# STM32WB30CEU6A register map
File version: 1.0
Registers are 32-bit, access not given, reset 0x0 unless marked. A register's access mark holds for its fields unless they carry their own. Offsets are from the block's base; [hi:lo] are bit positions; {n}, {i} and the like mark numbered series; 'fields as' and 'values as' point back to an identical list.

## TIM16
Base 0x40014400
Same registers: TIM17 0x40014800
0x00 CR1
  [11] UIFREMA, [9:8] CKD, [7] ARPE, [31:4] s, [3] OPM, [2] URS, [1] UDIS, [0] CEN
0x04 CR2
  [9] OIS1N, [8] OIS1, [3] CCDS, [2] CCUS, [31:1] s, [0] CCPC
0x0C DIER
  [9] CC1DE, [8] UDE, [7] BIE, [5] COMIE, [31:2] s, [1] CC1IE, [0] UIE
0x10 SR
  [9] CC1OF, [7] BIF, [5] COMIF, [31:2] s, [1] CC1IF, [0] UIF
0x14 EGR
  [7] BG, [5] COMG, [31:2] s, [1] CC1G, [0] UG
0x18 CCMR1_OUT
  [31:8] s, [16:4] OC1M, [3] OC1PE, [2] OC1FE, [1:0] CC1S
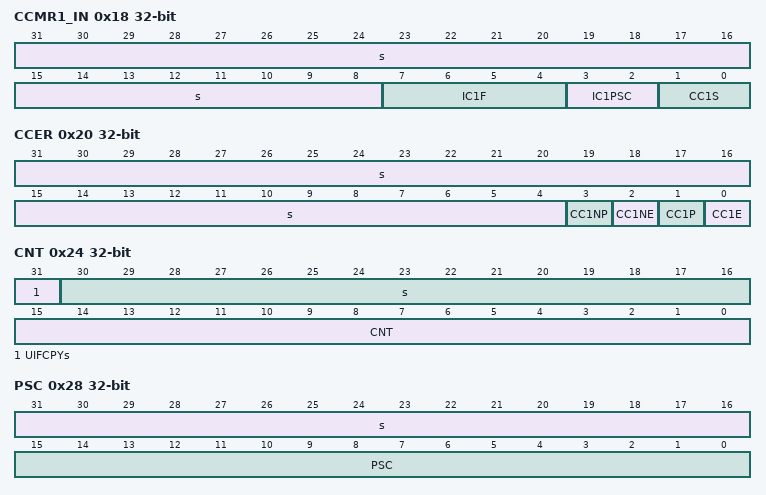
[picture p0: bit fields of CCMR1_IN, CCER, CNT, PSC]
0x18 CCMR1_IN
  [31:8] s, [7:4] IC1F, [3:2] IC1PSC, [1:0] CC1S
0x20 CCER
  [31:4] s, [3] CC1NP, [2] CC1NE, [1] CC1P, [0] CC1E
0x24 CNT
  [31] UIFCPYs, [30:16] s, [15:0] CNT
0x28 PSC
  [31:16] s, [15:0] PSC
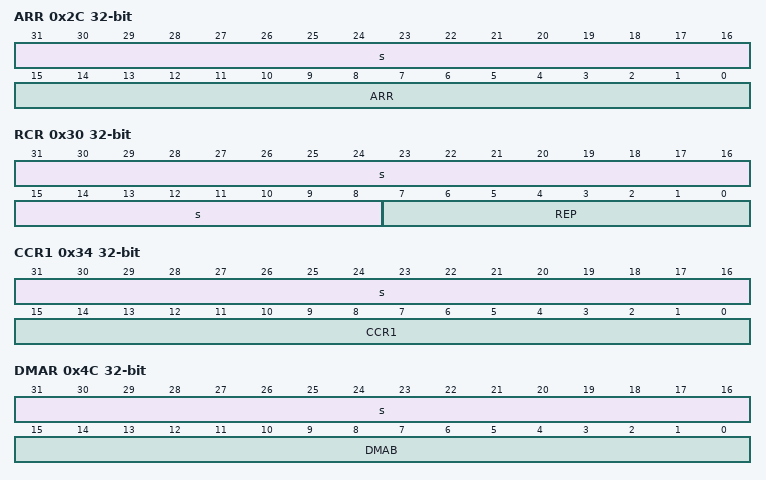
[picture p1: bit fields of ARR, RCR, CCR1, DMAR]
0x2C ARR
  [31:16] s, [15:0] ARR
0x30 RCR
  [31:8] s, [7:0] REP
0x34 CCR1
  [31:16] s, [15:0] CCR1
0x44 BDTR
  [28] BKBID, [26] BKDSRM, [31:16] s, [15] MOE, [14] AOE, [13] BKP, [12] BKE, [11] OSSR, [10] OSSI, [9:8] LOCK, [7:0] DTG
0x48 DCR
  [12:8] DBL, [31:5] s, [4:0] DBA
0x4C DMAR
  [31:16] s, [15:0] DMAB
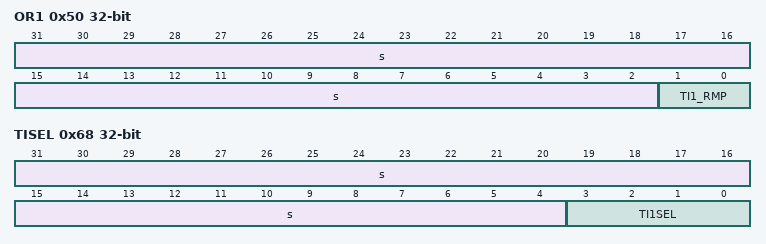
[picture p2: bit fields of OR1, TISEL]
0x50 OR1
  [31:2] s, [1:0] TI1_RMP
0x60 AF1
  [9] BKINP, [31:1] s, [0] BKINE
0x68 TISEL
  [31:4] s, [3:0] TI1SEL

## DMA1
Base 0x40020000
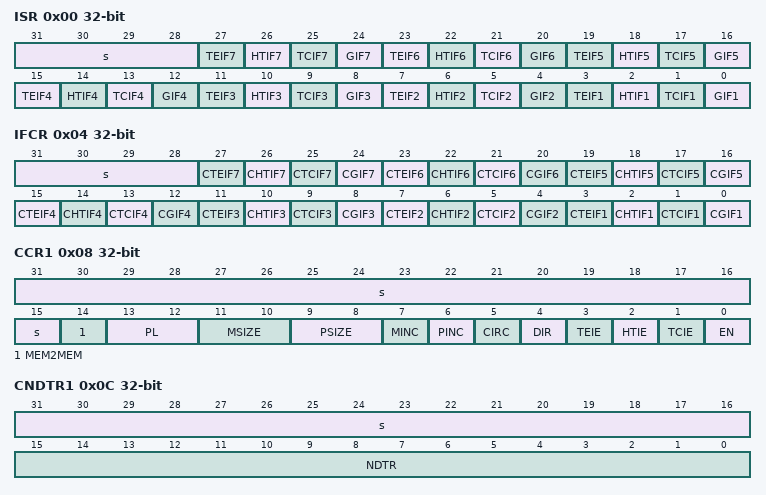
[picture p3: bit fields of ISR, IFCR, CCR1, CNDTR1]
0x00 ISR
  [31:28] s, [4n-1] TEIF{n} (n=1..7), [4n-2] HTIF{n} (n=1..7), [4n-3] TCIF{n} (n=1..7), [4n-4] GIF{n} (n=1..7)
0x04 IFCR
  [31:28] s, [4n-1] CTEIF{n} (n=1..7), [4n-2] CHTIF{n} (n=1..7), [4n-3] CTCIF{n} (n=1..7), [4n-4] CGIF{n} (n=1..7)
0x08 CCR1
  [31:15] s, [14] MEM2MEM, [13:12] PL, [11:10] MSIZE, [9:8] PSIZE, [7] MINC, [6] PINC, [5] CIRC, [4] DIR, [3] TEIE, [2] HTIE, [1] TCIE, [0] EN
0x0C CNDTR1
  [31:16] s, [15:0] NDTR
0x10 CPAR1
  [31:0] PA
{0x0+0x14*i} CMAR{i} (i=1..7)
  [31:0] MA
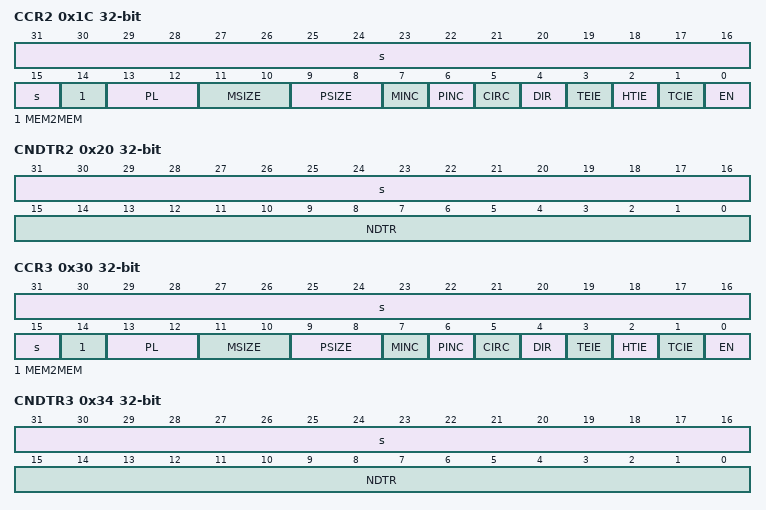
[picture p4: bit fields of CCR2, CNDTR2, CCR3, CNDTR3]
0x1C CCR2
  fields as CCR1
0x20 CNDTR2
  [31:16] s, [15:0] NDTR
0x24 CPAR2
  [31:0] PA
0x30 CCR3
  fields as CCR1
0x34 CNDTR3
  [31:16] s, [15:0] NDTR
0x38 CPAR3
  [31:0] PA
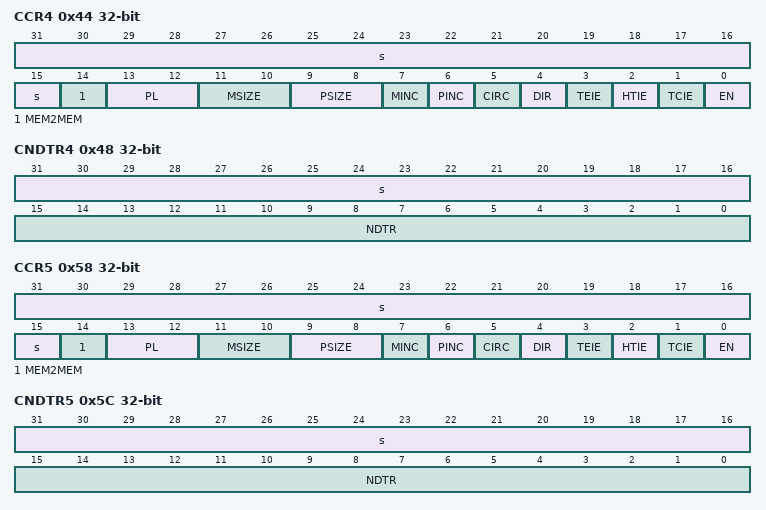
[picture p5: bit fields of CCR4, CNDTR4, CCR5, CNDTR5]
0x44 CCR4
  fields as CCR1
0x48 CNDTR4
  [31:16] s, [15:0] NDTR
0x4C CPAR4
  [31:0] PA
0x58 CCR5
  fields as CCR1
0x5C CNDTR5
  [31:16] s, [15:0] NDTR
0x60 CPAR5
  [31:0] PA
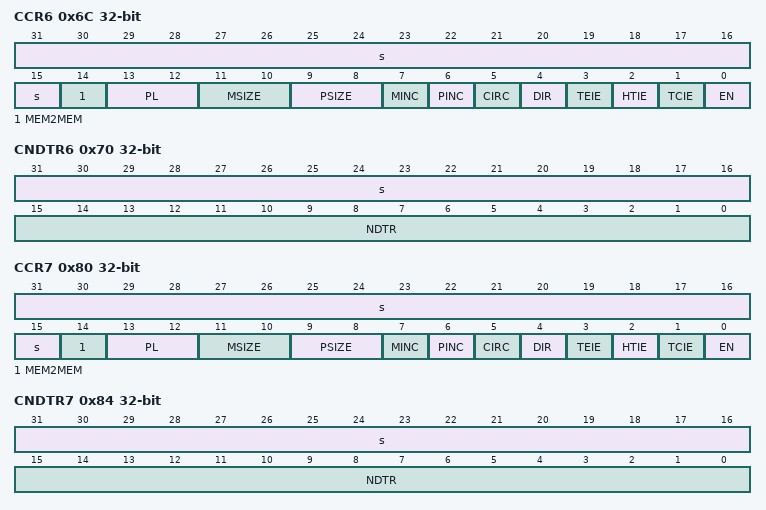
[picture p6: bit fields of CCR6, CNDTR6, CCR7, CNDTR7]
0x6C CCR6
  fields as CCR1
0x70 CNDTR6
  [31:16] s, [15:0] NDTR
0x74 CPAR6
  [31:0] PA
0x80 CCR7
  fields as CCR1
0x84 CNDTR7
  [31:16] s, [15:0] NDTR
0x88 CPAR7
  [31:0] PA

## DMAMUX
Base 0x40020800
{0x0+4i} C{i}CR (i=0..6)
  [28:24] SYNC_ID, [23:19] NBREQ, [18:17] SPOL, [16] SE, [9] EGE, [8] SOIE, [31:6] s, [5:0] DMAREQ_ID
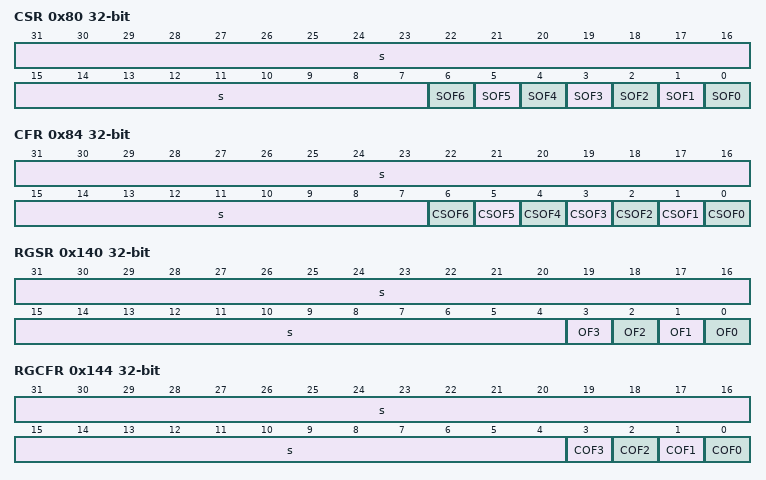
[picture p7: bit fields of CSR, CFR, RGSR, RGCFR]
0x80 CSR
  [31:7] s, [n] SOF{n} (n=0..6)
0x84 CFR
  [31:7] s, [n] CSOF{n} (n=0..6)
{0x100+4i} RG{i}CR (i=0..3)
  [23:19] GNBREQ, [18:17] GPOL, [16] GE, [8] OIE, [31:5] s, [4:0] SIG_ID
0x140 RGSR
  [31:4] s, [n] OF{n} (n=0..3)
0x144 RGCFR
  [31:4] s, [n] COF{n} (n=0..3)

## CRC
Base 0x40023000
0x00 DR
0x04 IDR
0x08 CR
  [7] REV_OUT, [6:5] REV_IN, [4:3] POLYSIZE, [31:1] s, [0] RESET
0x10 INIT
  [31:0] CRC_INIT
0x14 POL

## GPIOA
Base 0x48000000
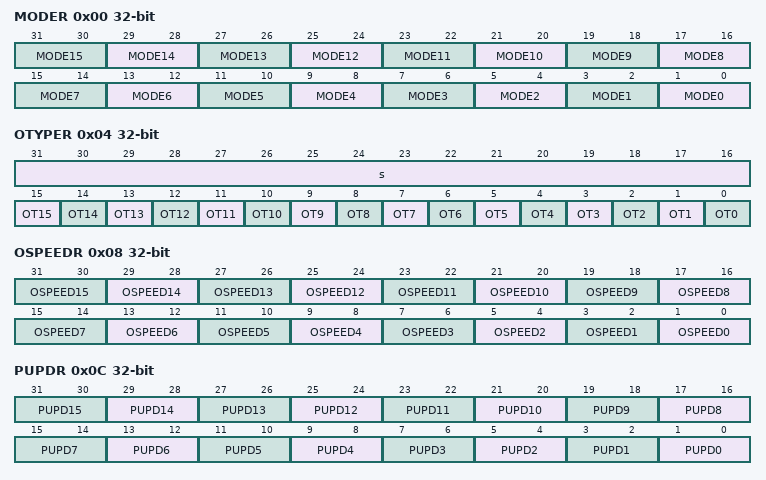
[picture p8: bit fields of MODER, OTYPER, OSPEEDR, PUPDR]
0x00 MODER
  [2n+1:2n] MODE{n} (n=0..15)
0x04 OTYPER
  [31:16] s, [n] OT{n} (n=0..15)
0x08 OSPEEDR
  [2n+1:2n] OSPEED{n} (n=0..15)
0x0C PUPDR
  [2n+1:2n] PUPD{n} (n=0..15)
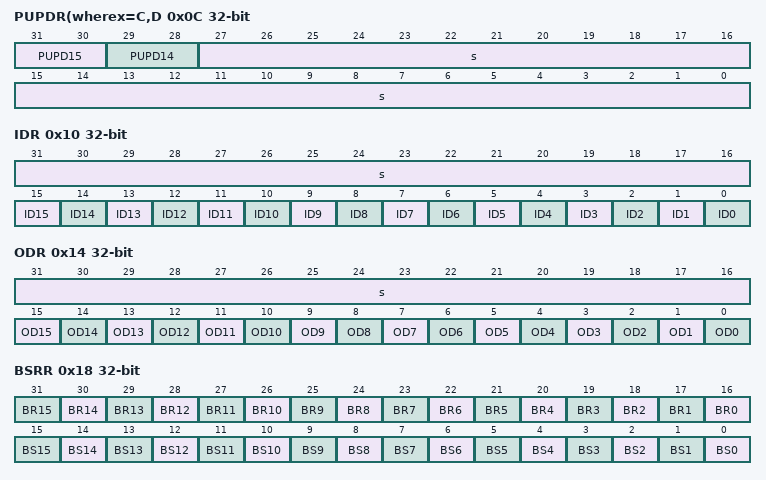
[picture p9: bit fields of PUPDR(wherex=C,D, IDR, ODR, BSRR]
0x0C PUPDR(wherex=C,D
  [31:30] PUPD15, [29:28] PUPD14, [27:0] s
0x10 IDR
  [31:16] s, [n] ID{n} (n=0..15)
0x14 ODR
  [31:16] s, [n] OD{n} (n=0..15)
0x18 BSRR
  [n+16] BR{n} (n=0..15), [n] BS{n} (n=0..15)
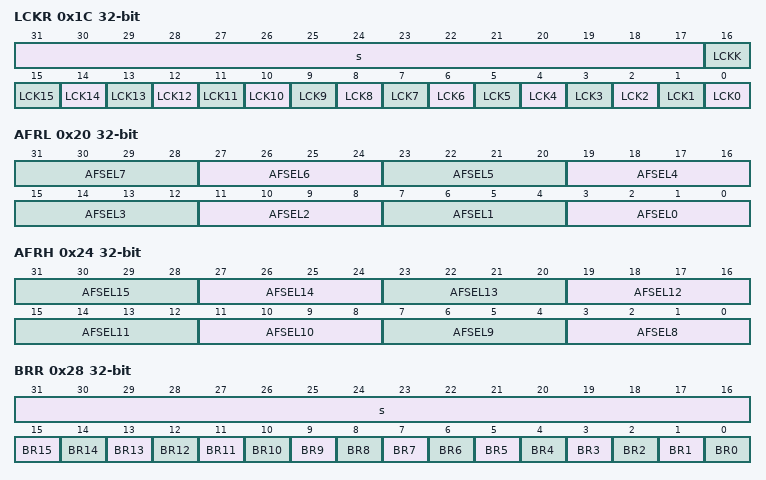
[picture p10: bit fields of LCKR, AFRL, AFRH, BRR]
0x1C LCKR
  [31:17] s, [16] LCKK, [n] LCK{n} (n=0..15)
0x20 AFRL
  [4n+3:4n] AFSEL{n} (n=0..7)
0x24 AFRH
  [4n-29:4n-32] AFSEL{n} (n=8..15)
0x28 BRR
  [31:16] s, [n] BR{n} (n=0..15)

## GPIOB
Base 0x48000400
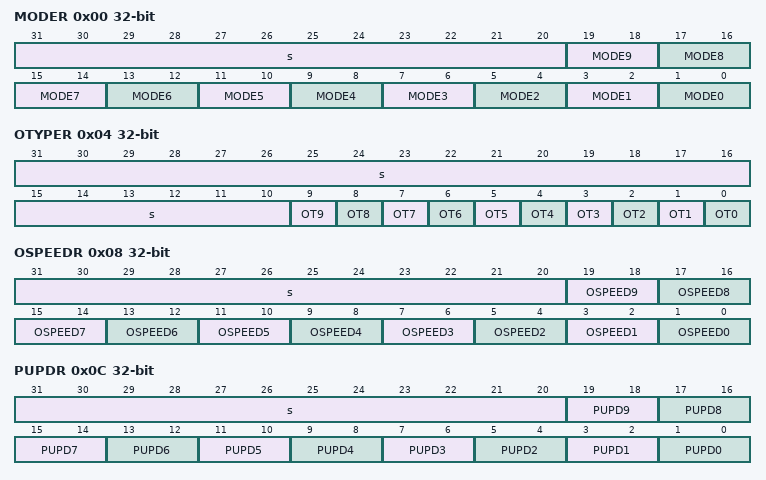
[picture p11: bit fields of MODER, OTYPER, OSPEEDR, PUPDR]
0x00 MODER
  [31:20] s, [2n+1:2n] MODE{n} (n=0..9)
0x04 OTYPER
  [31:10] s, [n] OT{n} (n=0..9)
0x08 OSPEEDR
  [31:20] s, [2n+1:2n] OSPEED{n} (n=0..9)
0x0C PUPDR
  [31:20] s, [2n+1:2n] PUPD{n} (n=0..9)
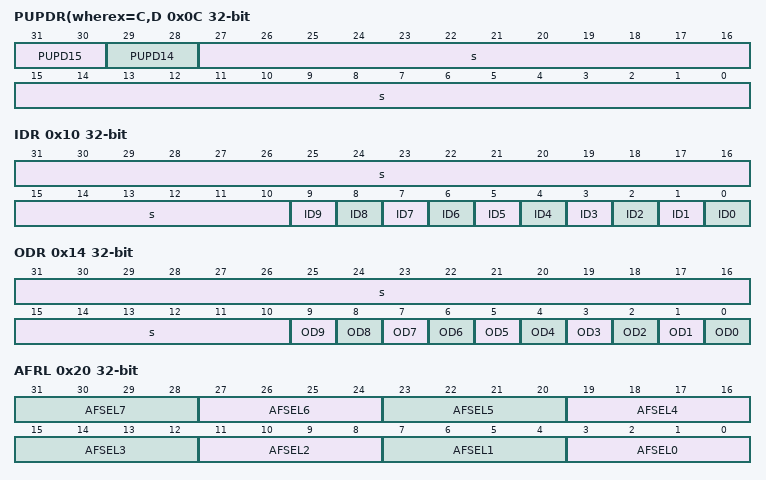
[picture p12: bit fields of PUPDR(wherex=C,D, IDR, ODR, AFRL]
0x0C PUPDR(wherex=C,D
  [31:30] PUPD15, [29:28] PUPD14, [27:0] s
0x10 IDR
  [31:10] s, [n] ID{n} (n=0..9)
0x14 ODR
  [31:10] s, [n] OD{n} (n=0..9)
0x18 BSRR
  [n+16] BR{n} (n=0..9), [31:10] s, [n] BS{n} (n=0..9)
0x1C LCKR
  [16] LCKK, [31:10] s, [n] LCK{n} (n=0..9)
0x20 AFRL
  [4n+3:4n] AFSEL{n} (n=0..7)
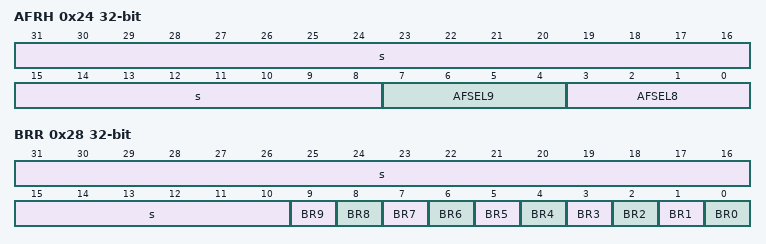
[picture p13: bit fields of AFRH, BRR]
0x24 AFRH
  [31:8] s, [7:4] AFSEL9, [3:0] AFSEL8
0x28 BRR
  [31:10] s, [n] BR{n} (n=0..9)
